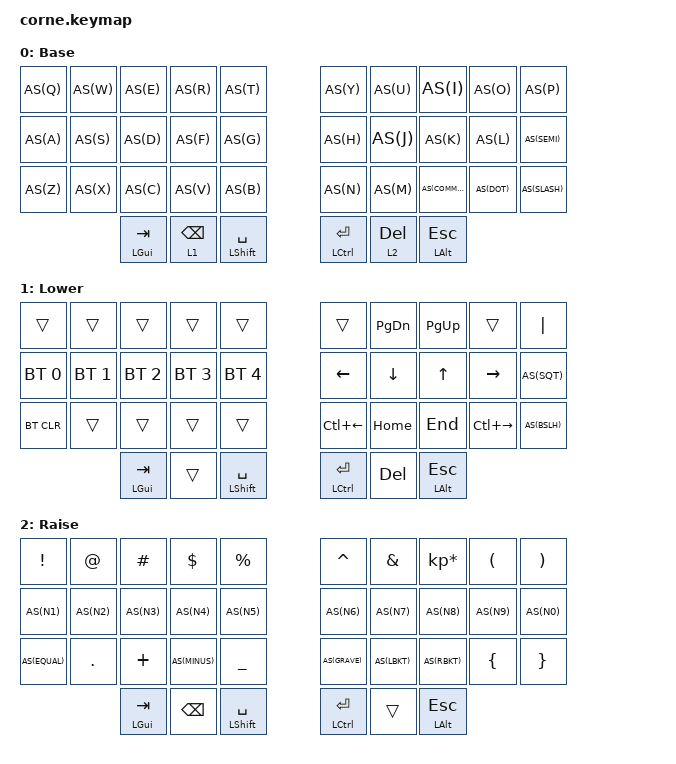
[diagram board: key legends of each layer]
/*
 * Copyright (c) 2020 The ZMK Contributors
 *
 * SPDX-License-Identifier: MIT
 */

#include <behaviors.dtsi>
#include <dt-bindings/zmk/keys.h>
#include <dt-bindings/zmk/bt.h>


#define AS(keycode) &as LS(keycode) keycode

/ {
    chosen {
        zmk,physical-layout = &foostan_corne_5col_layout;
    };

    behaviors {
        as: auto_shift {
            compatible = "zmk,behavior-hold-tap";
            #binding-cells = <2>;
            tapping_term_ms = <200>;
            quick_tap_ms = <0>;
            flavor = "tap-preferred";
            bindings = <&kp>, <&kp>;
        };
    };
        keymap {
                compatible = "zmk,keymap";

                default_layer {
// -----------------------------------------------------------------------------------------
// |  Q  |  W  |  E  |  R  |  T  |     |  Y  |  U   |  I   |  O   | P |
// |  A  |  S  |  D  |  F  |  G  |     |  H  |  J   |  K   |  L   | ' | 
// |  Z  |  X  |  C  |  V  |  B  |     |  N  |  M   | CTRL | META | . |
//             | GUI | LWR | SPC |     | ENT | RSE  | BSPC |
                        display-name = "Base";
                        bindings = <
   AS(Q) AS(W) AS(E) AS(R) AS(T)                  AS(Y)   AS(U)  AS(I)      AS(O)     AS(P)
   AS(A) AS(S) AS(D) AS(F) AS(G)                  AS(H)   AS(J)  AS(K)      AS(L)     AS(SEMI)
   AS(Z) AS(X) AS(C) AS(V) AS(B)                  AS(N)   AS(M)  AS(COMMA)  AS(DOT)   AS(SLASH)
   &mt LGUI TAB  &lt 1 BSPC  &mt LSHFT SPACE      &mt LCTRL RET  &lt 2 DEL  &mt LALT ESC
                        >;
                };

                lower_layer {
// -----------------------------------------------------------------------------------------
// | !     |  @  |  #  |  $  |  %  |     |  ^  |  &  |  *  |  (  |  )  |
// | BT1   | BT2 | BT3 | BT4 | BT5 |     | LFT | DWN |  UP | RGT |     |
// | BTCLR |     |     |     |     |     |     |     |     |     |     |
//               | GUI |     | SPC |     | ENT | ESC | TAB |
                        display-name = "Lower";
                        bindings = <
   &trans     &trans       &trans     &trans     &trans                 &trans        &kp PG_DN  &kp PG_UP   &trans         &kp PIPE
   &bt BT_SEL 0 &bt BT_SEL 1 &bt BT_SEL 2 &bt BT_SEL 3 &bt BT_SEL 4     &kp LEFT      &kp DOWN   &kp UP      &kp RIGHT      AS(SQT) 
   &bt BT_CLR   &trans       &trans       &trans       &trans           &kp LC(LEFT)  &kp HOME   &kp END     &kp LC(RIGHT)  AS(BSLH) 
   &mt LGUI TAB  &trans  &mt LSHFT SPACE                                &mt LCTRL RET  &kp DEL  &mt LALT ESC
                        >;
                };

                raise_layer {
// -----------------------------------------------------------------------------------------
// | 1! |  2@ |  3# |  4$ |  5% |     |  6^ |  7& |  8* |  9(  |  0)  |
// | -_ |  =+ |  {  |  [  |  (  |     |  )  |  ]  |  }  |  /?  |  \|  |
// | `~ |     |     |  ,< |  :  |     |  ;  |  .> | CTRL| META |      |
//            | GUI | ESC | SPC |     | ENT |     | TAB |
                        display-name = "Raise";
                        bindings = <

   &kp EXCL     &kp AT       &kp HASH     &kp DLLR     &kp PRCNT        &kp CARET  &kp AMPS   &kp KP_MULTIPLY  &kp LPAR  &kp RPAR
   AS(N1)       AS(N2)       AS(N3)       AS(N4)       AS(N5)           AS(N6)     AS(N7)     AS(N8)           AS(N9)    AS(N0)
   AS(EQUAL)    &kp DOT      &kp PLUS     AS(MINUS)    &kp UNDER        AS(GRAVE)  AS(LBKT)   AS(RBKT)         &kp LBRC  &kp RBRC
   &mt LGUI TAB  &kp BSPC  &mt LSHFT SPACE                              &mt LCTRL RET  &trans  &mt LALT ESC
                        >;
                };

                extra_1 {
                        status = "reserved";
                };

                extra_2 {
                        status = "reserved";
                };

                extra_3 {
                        status = "reserved";
                };
        };
};
